# DSS0_OVR2 register map
Vendor: Texas Instruments
Peripheral module from a debugger description file (folder J721S2).
Registers are 32-bit, read-write, reset 0x0 unless marked. A register's access mark holds for its fields unless they carry their own. Offsets are as the file gives them; lines under a group give offsets from that group; [hi:lo] are bit positions; {n}, {i} and the like mark numbered series; 'fields as' and 'values as' point back to an identical list; <NAME> marks a mode.

## DSS0_OVR2
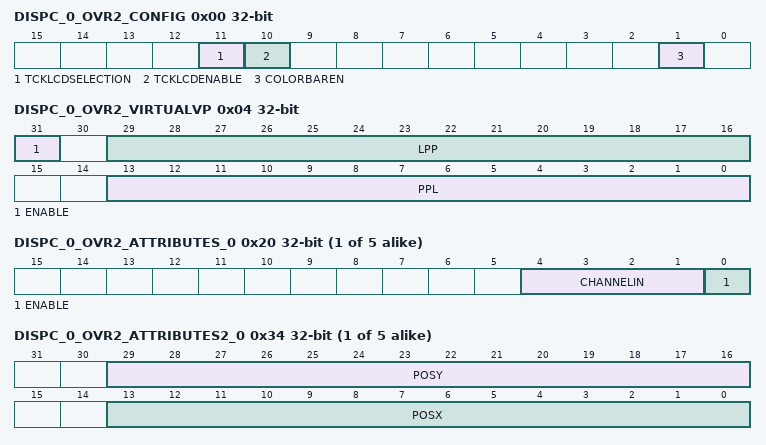
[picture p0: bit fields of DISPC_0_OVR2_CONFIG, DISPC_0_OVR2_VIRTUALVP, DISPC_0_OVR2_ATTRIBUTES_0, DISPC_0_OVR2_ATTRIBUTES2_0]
0x00 DISPC_0_OVR2_CONFIG access per field — The control register configures the Display Controller module for the VP output. Shadow register
  [11] TCKLCDSELECTION rw — Transparency Color Key Selection
  [10] TCKLCDENABLE rw — Transparency Color Key Enable
  [1] COLORBAREN rw — Enable the Color-Bar
0x04 DISPC_0_OVR2_VIRTUALVP — Configures the new VIRTUAL VP operation. Shadow register
  [31] ENABLE — Enable the Virtual VP Operation
  [29:16] LPP — Lines per panel Encoded value [from 1 to 16384] to specify the number of lines on the Virtual VP [program to value minus 1]
  [13:0] PPL — Pixels per line Encoded value [from 1 to 16384] to specify the number of pixels contains within each line on the Virtual VP [program to value minus 1]
0x08 DISPC_0_OVR2_DEFAULT_COLOR — The control register configures the default solid background color LSB[31:0]. Shadow register
  [31:0] DEFAULTCOLOR — 32-bit LSB of ARGB background color
0x0C DISPC_0_OVR2_DEFAULT_COLOR2 access per field — The control register configures the default solid background color MSB[47:32]. Shadow register
  [15:0] DEFAULTCOLOR rw — 16-bit MSB of ARGB background color
0x10 DISPC_0_OVR2_TRANS_COLOR_MAX — The register sets the max transparency color value for the overlays. Shadow register
  [31:0] TRANSCOLORKEY — LSB[31:0]. Transparency Color Key Value in 36-bit RGB format
0x14 DISPC_0_OVR2_TRANS_COLOR_MAX2 access per field — The register sets the max transparency color value for the overlays. Shadow register
  [3:0] TRANSCOLORKEY rw — MSB[35:32]. Transparency Color Key Value in 36-bit RGB format
0x18 DISPC_0_OVR2_TRANS_COLOR_MIN — The register sets the min transparency color value for the overlays. Shadow register
  fields as DISPC_0_OVR2_TRANS_COLOR_MAX
0x1C DISPC_0_OVR2_TRANS_COLOR_MIN2 access per field — The register sets the min transparency color value for the overlays. Shadow register
  fields as DISPC_0_OVR2_TRANS_COLOR_MAX2
{0x20+4i} DISPC_0_OVR2_ATTRIBUTES_{i} (i=0..4) — The register configures the attributes of layer-{i}, ZORDER= {i}, of the Overlay manager. Shadow register
  [4:1] CHANNELIN — Input channel connected to Layer
  [0] ENABLE — Layer Enable
{0x34+4i} DISPC_0_OVR2_ATTRIBUTES2_{i} (i=0..4) — The register configures the additional attributes of layer-{i}, ZORDER= {i}, of the Overlay manager. Shadow register
  [29:16] POSY — Y position of the layer. Encoded value [from 0 to 16383] to specify the Y position of the layer on the screen. The line at the top has the Y-position 0
  [13:0] POSX — X position of the layer. Encoded value [from 0 to 16383] to specify the X position of the layer on the screen. The first pixel on the left of the screen has the X-position 0
0x48 DISPC_0_OVR2_SECURE — Security bit settings for the sub-module
  [0] SECURE — Secure bit
